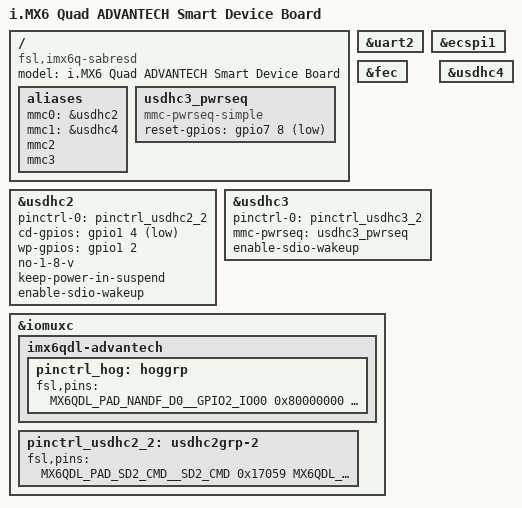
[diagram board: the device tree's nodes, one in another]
// SPDX-License-Identifier: GPL-2.0+
//
// Copyright 2012 Freescale Semiconductor, Inc.
// Copyright 2011 Linaro Ltd.

/dts-v1/;

#include "imx6q.dtsi"
#include "imx6qdl-advantech.dtsi"

/ {
	model = "i.MX6 Quad ADVANTECH Smart Device Board";
	compatible = "fsl,imx6q-sabresd", "fsl,imx6q";
        aliases {
                mmc0 = &usdhc2;
                mmc1 = &usdhc4;
                mmc2;
                mmc3;
        };
	usdhc3_pwrseq: usdhc3_pwrseq {
                compatible = "mmc-pwrseq-simple";
                reset-gpios = 	<&gpio7 8 GPIO_ACTIVE_LOW>; /* SD3_RESET# */
        };
};

&uart2 {
	status = "okay";
};

&ecspi1 {
	status = "okay";
};

&fec {
	status = "okay";
};

&usdhc2 {
        pinctrl-names = "default";
        pinctrl-0 = <&pinctrl_usdhc2_2>;
        cd-gpios = <&gpio1 4 GPIO_ACTIVE_LOW>;
        wp-gpios = <&gpio1 2 GPIO_ACTIVE_HIGH>;
        no-1-8-v;
	keep-power-in-suspend;
	enable-sdio-wakeup;
        status = "okay";
};

&usdhc3 {
	pinctrl-names = "default";
	pinctrl-0 = <&pinctrl_usdhc3_2>;
	mmc-pwrseq = <&usdhc3_pwrseq>;
	enable-sdio-wakeup;
	status = "okay";
};

&usdhc4 {
	status = "okay";
};

&iomuxc {
        imx6qdl-advantech {
		pinctrl_hog: hoggrp {
			fsl,pins = <
				MX6QDL_PAD_NANDF_D0__GPIO2_IO00 0x80000000
				MX6QDL_PAD_NANDF_D1__GPIO2_IO01 0x80000000
				MX6QDL_PAD_NANDF_D2__GPIO2_IO02 0x80000000
				MX6QDL_PAD_NANDF_D3__GPIO2_IO03 0x80000000
				MX6QDL_PAD_GPIO_0__CCM_CLKO1    0x130b0
				MX6QDL_PAD_ENET_TXD1__GPIO1_IO29 0x80000000
				MX6QDL_PAD_EIM_D22__GPIO3_IO22  0x80000000
				MX6QDL_PAD_ENET_CRS_DV__GPIO1_IO25 0x80000000
				//MX6QDL_PAD_EIM_D26__GPIO3_IO26 0x80000000 /*rsb3430 uboot uart fail*/
				MX6QDL_PAD_EIM_CS1__GPIO2_IO24 0x80000000
				MX6QDL_PAD_ENET_RXD0__GPIO1_IO27 0x80000000
				MX6QDL_PAD_EIM_A25__GPIO5_IO02 0x80000000
				MX6QDL_PAD_EIM_D23__GPIO3_IO23 0x80000000
				MX6QDL_PAD_EIM_EB3__GPIO2_IO31 0x80000000
				MX6QDL_PAD_SD1_CMD__GPIO1_IO18 0x80000000
				MX6QDL_PAD_EIM_D16__GPIO3_IO16 0x80000000
				MX6QDL_PAD_SD3_RST__GPIO7_IO08	0x80000000
				MX6QDL_PAD_GPIO_9__GPIO1_IO09 	0x80000000
				MX6QDL_PAD_EIM_DA9__GPIO3_IO09 0x80000000
				MX6QDL_PAD_NANDF_CS0__GPIO6_IO11 0x80000000
				MX6QDL_PAD_NANDF_CS1__GPIO6_IO14 0x80000000
				MX6QDL_PAD_NANDF_CS2__GPIO6_IO15 0x80000000
				MX6QDL_PAD_NANDF_CS3__GPIO6_IO16 0x80000000
			>;
		};
        };
        pinctrl_usdhc2_2: usdhc2grp-2 {
                fsl,pins = <
                        MX6QDL_PAD_SD2_CMD__SD2_CMD             0x17059
                        MX6QDL_PAD_SD2_CLK__SD2_CLK             0x10059
                        MX6QDL_PAD_SD2_DAT0__SD2_DATA0          0x17059
                        MX6QDL_PAD_SD2_DAT1__SD2_DATA1          0x17059
                        MX6QDL_PAD_SD2_DAT2__SD2_DATA2          0x17059
                        MX6QDL_PAD_SD2_DAT3__SD2_DATA3          0x17059
                        MX6QDL_PAD_GPIO_4__GPIO1_IO04           0x80000000      /* SD2_CD */
                        MX6QDL_PAD_GPIO_2__GPIO1_IO02           0x80000000      /* SD2_WP */
                >;
        };
};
